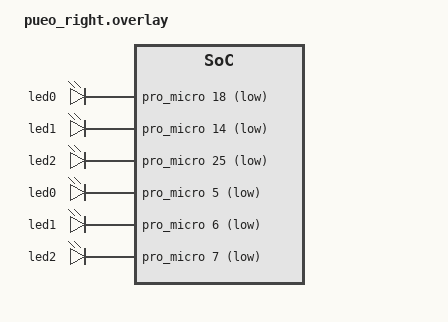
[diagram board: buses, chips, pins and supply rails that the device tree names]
/*
 * Copyright (c) 2024 The ZMK Contributors
 *
 * SPDX-License-Identifier: MIT
 */
 
#include <dt-bindings/zmk/matrix_transform.h>
#include <physical_layouts.dtsi>
#include "pueo.dtsi"

&default_transform {
	col-offset = <13>;
};

&kscan_faceup {
	input-gpios
	= <&pro_micro 10 (GPIO_ACTIVE_LOW | GPIO_PULL_UP)>
	, <&pro_micro 19 (GPIO_ACTIVE_LOW | GPIO_PULL_UP)>
	, <&pro_micro 2  (GPIO_ACTIVE_LOW | GPIO_PULL_UP)>
	, <&pro_micro 5  (GPIO_ACTIVE_LOW | GPIO_PULL_UP)>
	, <&pro_micro 16 (GPIO_ACTIVE_LOW | GPIO_PULL_UP)>
	, <&pro_micro 20 (GPIO_ACTIVE_LOW | GPIO_PULL_UP)>
	, <&pro_micro 3  (GPIO_ACTIVE_LOW | GPIO_PULL_UP)>
	, <&pro_micro 6  (GPIO_ACTIVE_LOW | GPIO_PULL_UP)>
	, <&pro_micro 21 (GPIO_ACTIVE_LOW | GPIO_PULL_UP)>
	, <&pro_micro 10 (GPIO_ACTIVE_LOW | GPIO_PULL_UP)>
	, <&pro_micro 7  (GPIO_ACTIVE_LOW | GPIO_PULL_UP)>
	, <&pro_micro 8  (GPIO_ACTIVE_LOW | GPIO_PULL_UP)>
	, <&pro_micro 9  (GPIO_ACTIVE_LOW | GPIO_PULL_UP)>
	;

    leds {
        compatible = "gpio-leds";
        status = "okay";
        led0: led_0 {
            gpios = <&pro_micro 18 GPIO_ACTIVE_LOW>;  // red LED, connected to P0.18
        };
        led1: led_1 {
            gpios = <&pro_micro 14 GPIO_ACTIVE_LOW>;  // green LED, connected to P0.14
        };
        led2: led_2 {
            gpios = <&pro_micro 25 GPIO_ACTIVE_LOW>;  // blue LED, connected to P0.25
        };
    };
};

&kscan_facedown {
	input-gpios
	= <&pro_micro 9  (GPIO_ACTIVE_LOW | GPIO_PULL_UP)>
	, <&pro_micro 4  (GPIO_ACTIVE_LOW | GPIO_PULL_UP)>
	, <&pro_micro 21 (GPIO_ACTIVE_LOW | GPIO_PULL_UP)>
	, <&pro_micro 18 (GPIO_ACTIVE_LOW | GPIO_PULL_UP)>
	, <&pro_micro 8  (GPIO_ACTIVE_LOW | GPIO_PULL_UP)>
	, <&pro_micro 3  (GPIO_ACTIVE_LOW | GPIO_PULL_UP)>
	, <&pro_micro 20 (GPIO_ACTIVE_LOW | GPIO_PULL_UP)>
	, <&pro_micro 15 (GPIO_ACTIVE_LOW | GPIO_PULL_UP)>
	, <&pro_micro 2  (GPIO_ACTIVE_LOW | GPIO_PULL_UP)>
	, <&pro_micro 19 (GPIO_ACTIVE_LOW | GPIO_PULL_UP)>
	, <&pro_micro 14 (GPIO_ACTIVE_LOW | GPIO_PULL_UP)>
	, <&pro_micro 16 (GPIO_ACTIVE_LOW | GPIO_PULL_UP)>
	, <&pro_micro 10 (GPIO_ACTIVE_LOW | GPIO_PULL_UP)>
	;

    leds {
        compatible = "gpio-leds";
        status = "okay";
        led0: led_0 {
            gpios = <&pro_micro 5 GPIO_ACTIVE_LOW>;  // red LED, connected to P0.05
        };
        led1: led_1 {
            gpios = <&pro_micro 6 GPIO_ACTIVE_LOW>;  // green LED, connected to P0.06
        };
        led2: led_2 {
            gpios = <&pro_micro 7 GPIO_ACTIVE_LOW>;  // blue LED, connected to P0.07
        };
    };
};
